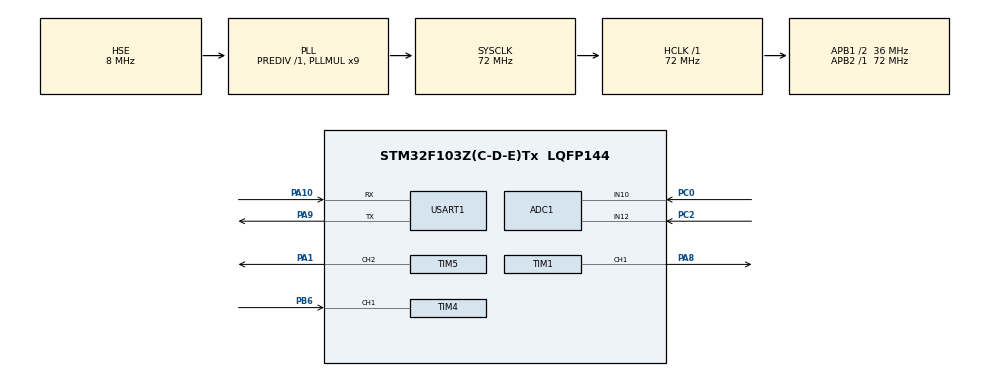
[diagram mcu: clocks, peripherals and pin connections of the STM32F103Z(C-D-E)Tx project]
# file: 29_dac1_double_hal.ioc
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ADC1.Channel-0\#ChannelRegularConversion=ADC_CHANNEL_10
ADC1.Channel-1\#ChannelRegularConversion=ADC_CHANNEL_12
ADC1.ContinuousConvMode=ENABLE
ADC1.NbrOfConversion=2
ADC1.NbrOfConversionFlag=1
ADC1.Rank-0\#ChannelRegularConversion=1
ADC1.Rank-1\#ChannelRegularConversion=2
ADC1.SamplingTime-0\#ChannelRegularConversion=ADC_SAMPLETIME_7CYCLES_5
ADC1.SamplingTime-1\#ChannelRegularConversion=ADC_SAMPLETIME_7CYCLES_5
ADC1.master=1
Dma.ADC1.2.Direction=DMA_PERIPH_TO_MEMORY
Dma.ADC1.2.Instance=DMA1_Channel1
Dma.ADC1.2.MemDataAlignment=DMA_MDATAALIGN_HALFWORD
Dma.ADC1.2.MemInc=DMA_MINC_ENABLE
Dma.ADC1.2.Mode=DMA_CIRCULAR
Dma.ADC1.2.PeriphDataAlignment=DMA_PDATAALIGN_HALFWORD
Dma.ADC1.2.PeriphInc=DMA_PINC_DISABLE
Dma.ADC1.2.Priority=DMA_PRIORITY_LOW
Dma.Request0=USART1_TX
Dma.Request1=USART1_RX
Dma.Request2=ADC1
Dma.USART1_RX.1.Direction=DMA_PERIPH_TO_MEMORY
Dma.USART1_RX.1.Instance=DMA1_Channel5
Dma.USART1_RX.1.MemDataAlignment=DMA_MDATAALIGN_BYTE
Dma.USART1_RX.1.MemInc=DMA_MINC_ENABLE
Dma.USART1_RX.1.Mode=DMA_CIRCULAR
Dma.USART1_RX.1.PeriphDataAlignment=DMA_PDATAALIGN_BYTE
Dma.USART1_RX.1.PeriphInc=DMA_PINC_DISABLE
Dma.USART1_RX.1.Priority=DMA_PRIORITY_LOW
Dma.USART1_TX.0.Direction=DMA_MEMORY_TO_PERIPH
Dma.USART1_TX.0.Instance=DMA1_Channel4
Dma.USART1_TX.0.MemDataAlignment=DMA_MDATAALIGN_BYTE
Dma.USART1_TX.0.MemInc=DMA_MINC_ENABLE
Dma.USART1_TX.0.Mode=DMA_NORMAL
Dma.USART1_TX.0.PeriphDataAlignment=DMA_PDATAALIGN_BYTE
Dma.USART1_TX.0.PeriphInc=DMA_PINC_DISABLE
Dma.USART1_TX.0.Priority=DMA_PRIORITY_LOW
Mcu.Family=STM32F1
Mcu.Name=STM32F103Z(C-D-E)Tx
Mcu.Package=LQFP144
NVIC.DMA1_Channel4_IRQn=true\:0\:0\:false\:false\:true\:false\:true\:true
NVIC.DMA1_Channel5_IRQn=true\:0\:0\:false\:false\:true\:true\:true\:true
NVIC.PriorityGroup=NVIC_PRIORITYGROUP_4
OSC_IN.Mode=HSE-External-Oscillator
OSC_IN.Signal=RCC_OSC_IN
OSC_OUT.Mode=HSE-External-Oscillator
OSC_OUT.Signal=RCC_OSC_OUT
PA1.Signal=S_TIM5_CH2
PA10.Mode=Asynchronous
PA10.Signal=USART1_RX
PA13.Mode=Serial_Wire
PA13.Signal=SYS_JTMS-SWDIO
PA14.Mode=Serial_Wire
PA14.Signal=SYS_JTCK-SWCLK
PA8.Signal=S_TIM1_CH1
PA9.Mode=Asynchronous
PA9.Signal=USART1_TX
PB6.Signal=S_TIM4_CH1
PC0.Signal=ADCx_IN10
PC14-OSC32_IN.Mode=LSE-External-Oscillator
PC14-OSC32_IN.Signal=RCC_OSC32_IN
PC15-OSC32_OUT.Mode=LSE-External-Oscillator
PC15-OSC32_OUT.Signal=RCC_OSC32_OUT
PC2.Signal=ADCx_IN12
ProjectManager.HeapSize=0x200
ProjectManager.StackSize=0x400
ProjectManager.TargetToolchain=MDK-ARM V5.32
RCC.ADCPresc=RCC_ADCPCLK2_DIV6
RCC.AHBFreq_Value=72000000
RCC.APB1CLKDivider=RCC_HCLK_DIV2
RCC.APB1Freq_Value=36000000
RCC.APB1TimFreq_Value=72000000
RCC.APB2Freq_Value=72000000
RCC.APB2TimFreq_Value=72000000
RCC.HCLKFreq_Value=72000000
RCC.PLLMUL=RCC_PLL_MUL9
RCC.PLLSourceVirtual=RCC_PLLSOURCE_HSE
RCC.SYSCLKFreq_VALUE=72000000
RCC.SYSCLKSource=RCC_SYSCLKSOURCE_PLLCLK
RCC.USBFreq_Value=72000000
SH.ADCx_IN10.0=ADC1_IN10,IN10
SH.ADCx_IN12.0=ADC1_IN12,IN12
SH.S_TIM1_CH1.0=TIM1_CH1,PWM Generation1 CH1
SH.S_TIM4_CH1.0=TIM4_CH1,Input_Capture1_from_TI1
SH.S_TIM4_CH1.1=TIM4_CH1,TriggerSource_TI1FP1
SH.S_TIM5_CH2.0=TIM5_CH2,PWM Generation2 CH2
TIM1.Channel-PWM\ Generation1\ CH1=TIM_CHANNEL_1
TIM1.OCIdleState_1=TIM_OCIDLESTATE_SET
TIM1.Period=5000-1
TIM1.Prescaler=7200-1
TIM1.Pulse-PWM\ Generation1\ CH1=2500
TIM1.RepetitionCounter=5-1
TIM4.Channel-Input_Capture1_from_TI1=TIM_CHANNEL_1
TIM4.Channel-Input_Capture2_from_TI1_63=TIM_CHANNEL_2
TIM4.ICPolarity_CH2=TIM_INPUTCHANNELPOLARITY_FALLING
TIM4.Prescaler=72-1
TIM5.Channel-PWM\ Generation2\ CH2=TIM_CHANNEL_2
TIM5.OCPolarity_2=TIM_OCPOLARITY_LOW
TIM5.Period=100-1
TIM5.Prescaler=7200-1
TIM5.Pulse-PWM\ Generation2\ CH2=50
USART1.VirtualMode=VM_ASYNC
VP_TIM1_VS_ClockSourceINT.Mode=Internal
VP_TIM1_VS_OPM.Mode=OPM_bit
VP_TIM4_VS_ClockSourceINT.Mode=Internal
VP_TIM4_VS_ControllerModeReset.Mode=Reset Mode
VP_TIM4_VS_indirect_ch1.Mode=Input_Capture2_from_TI1_63
VP_TIM5_VS_ClockSourceINT.Mode=Internal
board=custom

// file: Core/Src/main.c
/* USER CODE BEGIN Header */
/**
 ******************************************************************************
 * @file           : main.c
 * @brief          : Main program body
 ******************************************************************************
 * @attention
 *
 * Copyright (c) 2026 STMicroelectronics.
 * All rights reserved.
 *
 * This software is licensed under terms that can be found in the LICENSE file
 * in the root directory of this software component.
 * If no LICENSE file comes with this software, it is provided AS-IS.
 *
 ******************************************************************************
 */
/* USER CODE END Header */
#include "main.h"
#include "adc.h"
#include "dma.h"
#include "tim.h"
#include "usart.h"
#include "gpio.h"

/* USER CODE BEGIN Includes */
#include "stdio.h"
/* USER CODE END Includes */

void SystemClock_Config(void);

/* USER CODE BEGIN 0 */
extern uint8_t usart1_dma_rx_complete_flag;
/* USER CODE END 0 */

int main(void)
{

  /* MCU Configuration--------------------------------------------------------*/

  /* Reset of all peripherals, Initializes the Flash interface and the Systick. */
  HAL_Init();

  /* Configure the system clock */
  SystemClock_Config();

  /* Initialize all configured peripherals */
  MX_GPIO_Init();
  MX_DMA_Init();
  MX_TIM4_Init();
  MX_TIM5_Init();
  MX_USART1_UART_Init();
  MX_TIM1_Init();
  MX_ADC1_Init();
  /* USER CODE BEGIN 2 */

    // ADC校准，一定要放在启动之前
    HAL_ADCEx_Calibration_Start(&hadc1);
    // 启动ADC转换
    uint16_t buffer[2] = {0};
    HAL_ADC_Start_DMA(&hadc1, (uint32_t *)buffer, 2);

  /* USER CODE END 2 */

  /* Infinite loop */
  /* USER CODE BEGIN WHILE */
    while (1)
    {
      printf("PC0 = %.2fV  PC2 = %.2fV", buffer[0] * 3.3 / 4095, buffer[1] * 3.3 / 4095);
      HAL_Delay(1000);
    /* USER CODE END WHILE */

    }
}

void SystemClock_Config(void)
{
  RCC_OscInitTypeDef RCC_OscInitStruct = {0};
  RCC_ClkInitTypeDef RCC_ClkInitStruct = {0};
  RCC_PeriphCLKInitTypeDef PeriphClkInit = {0};

  /** Initializes the RCC Oscillators according to the specified parameters
  * in the RCC_OscInitTypeDef structure.
  */
  RCC_OscInitStruct.OscillatorType = RCC_OSCILLATORTYPE_HSE;
  RCC_OscInitStruct.HSEState = RCC_HSE_ON;
  RCC_OscInitStruct.HSEPredivValue = RCC_HSE_PREDIV_DIV1;
  RCC_OscInitStruct.HSIState = RCC_HSI_ON;
  RCC_OscInitStruct.PLL.PLLState = RCC_PLL_ON;
  RCC_OscInitStruct.PLL.PLLSource = RCC_PLLSOURCE_HSE;
  RCC_OscInitStruct.PLL.PLLMUL = RCC_PLL_MUL9;
  if (HAL_RCC_OscConfig(&RCC_OscInitStruct) != HAL_OK)
  {
    Error_Handler();
  }

  /** Initializes the CPU, AHB and APB buses clocks
  */
  RCC_ClkInitStruct.ClockType = RCC_CLOCKTYPE_HCLK|RCC_CLOCKTYPE_SYSCLK
                              |RCC_CLOCKTYPE_PCLK1|RCC_CLOCKTYPE_PCLK2;
  RCC_ClkInitStruct.SYSCLKSource = RCC_SYSCLKSOURCE_PLLCLK;
  RCC_ClkInitStruct.AHBCLKDivider = RCC_SYSCLK_DIV1;
  RCC_ClkInitStruct.APB1CLKDivider = RCC_HCLK_DIV2;
  RCC_ClkInitStruct.APB2CLKDivider = RCC_HCLK_DIV1;

  if (HAL_RCC_ClockConfig(&RCC_ClkInitStruct, FLASH_LATENCY_2) != HAL_OK)
  {
    Error_Handler();
  }
  PeriphClkInit.PeriphClockSelection = RCC_PERIPHCLK_ADC;
  PeriphClkInit.AdcClockSelection = RCC_ADCPCLK2_DIV6;
  if (HAL_RCCEx_PeriphCLKConfig(&PeriphClkInit) != HAL_OK)
  {
    Error_Handler();
  }
}

void Error_Handler(void)
{
    __disable_irq();
    while (1)
    {
    }
}
